# ATSAMG55J19 device description
Architecture: CORTEX-M4; Family: SAMG; Series: SAMG55
Registers are 32-bit, read-write, no defined reset value unless marked. A register's access mark holds for its fields unless they carry their own. Offsets are from the block's base; [hi:lo] are bit positions; {n}, {i} and the like mark numbered series.

## PMC — Power Management Controller
Instances: PMC 0x400E0400
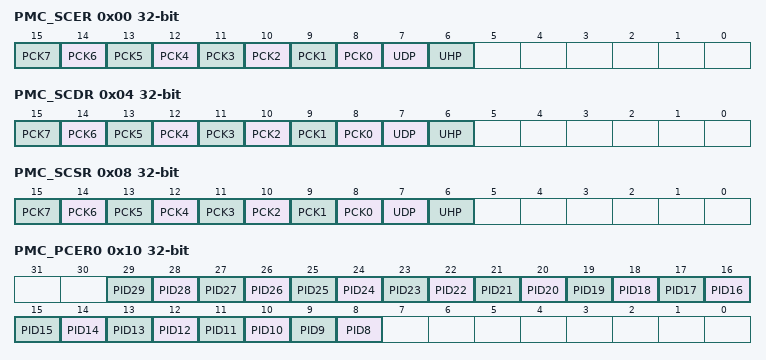
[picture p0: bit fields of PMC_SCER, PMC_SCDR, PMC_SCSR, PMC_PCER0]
0x00 PMC_SCER wo (atomic set of PMC_SCSR) — System Clock Enable Register
  [n+8] PCK{n} (n=0..7) — Programmable Clock {n} Output Enable
  [7] UDP — USB Device Port Clock Enable
  [6] UHP — USB Host Port Clock Enable
0x04 PMC_SCDR wo (atomic clear of PMC_SCSR) — System Clock Disable Register
  [n+8] PCK{n} (n=0..7) — Programmable Clock {n} Output Disable
  [7] UDP
  [6] UHP — USB Host Port Clock Disable
0x08 PMC_SCSR ro — System Clock Status Register
  [n+8] PCK{n} (n=0..7) — Programmable Clock {n} Output Status
  [7] UDP
  [6] UHP — USB Host Port Clock Status
0x10 PMC_PCER0 wo (atomic set of PMC_PCSR0) — Peripheral Clock Enable Register 0
  [n] PID{n} (n=8..29) — Peripheral Clock {n} Enable
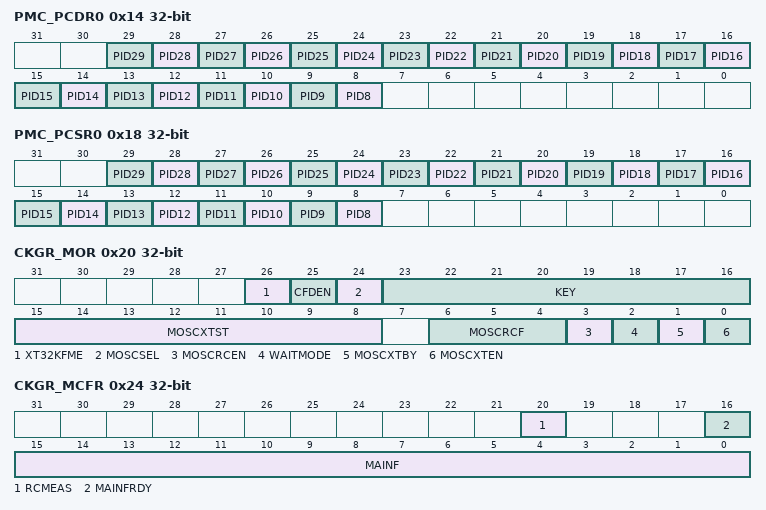
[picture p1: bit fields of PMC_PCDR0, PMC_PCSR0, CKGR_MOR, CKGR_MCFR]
0x14 PMC_PCDR0 wo (atomic clear of PMC_PCSR0) — Peripheral Clock Disable Register 0
  [n] PID{n} (n=8..29) — Peripheral Clock {n} Disable
0x18 PMC_PCSR0 ro — Peripheral Clock Status Register 0
  [n] PID{n} (n=8..29) — Peripheral Clock {n} Status
0x20 CKGR_MOR — Main Oscillator Register
  [26] XT32KFME — 32.768 kHz Crystal Oscillator Frequency Monitoring Enable
  [25] CFDEN — Clock Failure Detector Enable
  [24] MOSCSEL — Main Oscillator Selection
  [23:16] KEY — Write Access Password
    55=PASSWD (Writing any other value in this field aborts the write operation.Always reads as 0.)
  [15:8] MOSCXTST — Main Crystal Oscillator Start-up Time
  [6:4] MOSCRCF — Main On-Chip RC Oscillator Frequency Selection
    0=_8_MHz (The Fast RC Oscillator frequency is at 8 MHz (default)); 1=_16_MHz (The Fast RC Oscillator frequency is at 16 MHz); 2=_24_MHz (The Fast RC Oscillator frequency is at 24 MHz)
  [3] MOSCRCEN — Main On-Chip RC Oscillator Enable
  [2] WAITMODE — Wait Mode Command (Write-only)
  [1] MOSCXTBY — Main Crystal Oscillator Bypass
  [0] MOSCXTEN — Main Crystal Oscillator Enable
0x24 CKGR_MCFR — Main Clock Frequency Register
  [20] RCMEAS — RC Oscillator Frequency Measure (write-only)
  [16] MAINFRDY — Main Clock Frequency Measure Ready
  [15:0] MAINF — Main Clock Frequency
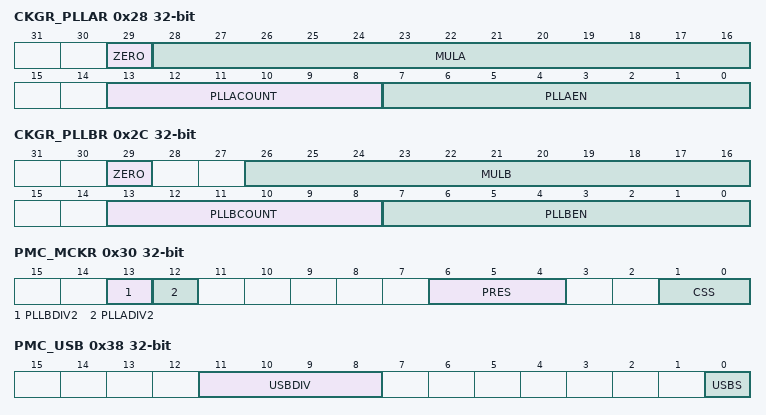
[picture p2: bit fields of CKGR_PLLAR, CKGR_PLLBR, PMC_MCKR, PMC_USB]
0x28 CKGR_PLLAR — PLLA Register
  [29] ZERO — Must Be Written to 0
  [28:16] MULA — PLLA Multiplier
  [13:8] PLLACOUNT — PLLA Counter
  [7:0] PLLAEN — PLLA Control
0x2C CKGR_PLLBR — PLLB Register
  [29] ZERO — Must Be Written to 0
  [26:16] MULB — PLLB Multiplier
  [13:8] PLLBCOUNT — PLLB Counter
  [7:0] PLLBEN — PLLB Control
0x30 PMC_MCKR — Master Clock Register
  [13] PLLBDIV2
  [12] PLLADIV2 — PLLA Divisor by 2
  [6:4] PRES — Processor Clock Prescaler
    0=CLK_1 (Selected clock); 1=CLK_2 (Selected clock divided by 2); 2=CLK_4 (Selected clock divided by 4); 3=CLK_8 (Selected clock divided by 8); 4=CLK_16 (Selected clock divided by 16); 5=CLK_32 (Selected clock divided by 32); 6=CLK_64 (Selected clock divided by 64); 7=CLK_3 (Selected clock divided by 3)
  [1:0] CSS — Master Clock Source Selection
    0=SLOW_CLK (Slow Clock is selected); 1=MAIN_CLK (Main Clock is selected); 2=PLLA_CLK (PLLA Clock is selected); 3=PLLB_CLK (PLLBClock is selected)
0x38 PMC_USB — USB Clock Register
  [11:8] USBDIV — Divider for USB Clock
  [0] USBS — USB Input Clock Selection
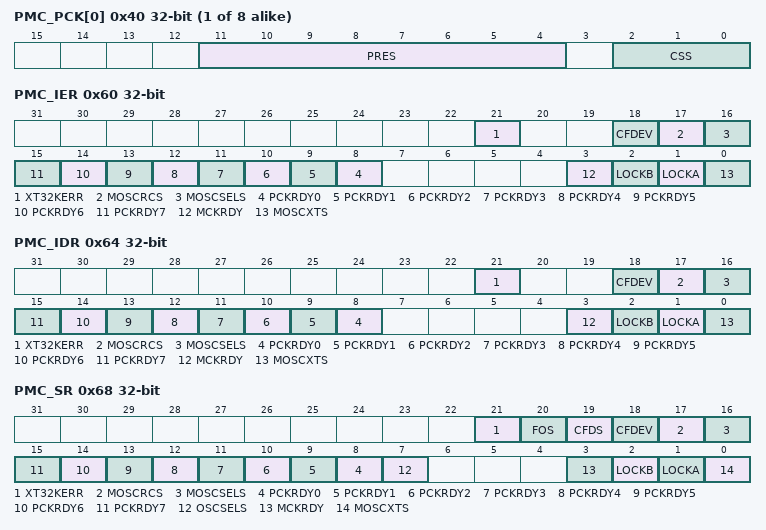
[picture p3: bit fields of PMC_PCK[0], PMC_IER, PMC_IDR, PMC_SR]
{0x40+4i} PMC_PCK[{i}] (i=0..7) — Programmable Clock 0 Register 0
  [11:4] PRES — Programmable Clock Prescaler
  [2:0] CSS — Master Clock Source Selection
    0=SLOW_CLK (Slow Clock is selected); 1=MAIN_CLK (Main Clock is selected); 2=PLLA_CLK (PLLA Clock is selected); 3=PLLB_CLK (PLLB Clock is selected); 4=MCK (Master Clock is selected)
0x60 PMC_IER wo (atomic set of PMC_IMR) — Interrupt Enable Register
  [21] XT32KERR — 32.768 kHz Crystal Oscillator Error Interrupt Enable
  [18] CFDEV — Clock Failure Detector Event Interrupt Enable
  [17] MOSCRCS — Main On-Chip RC Status Interrupt Enable
  [16] MOSCSELS — Main Oscillator Selection Status Interrupt Enable
  [n+8] PCKRDY{n} (n=0..7) — Programmable Clock Ready {n} Interrupt Enable
  [3] MCKRDY — Master Clock Ready Interrupt Enable
  [2] LOCKB — PLLB Lock Interrupt Enable
  [1] LOCKA — PLLA Lock Interrupt Enable
  [0] MOSCXTS — Main Crystal Oscillator Status Interrupt Enable
0x64 PMC_IDR wo (atomic clear of PMC_IMR) — Interrupt Disable Register
  [21] XT32KERR — 32.768 kHz Crystal Oscillator Error Interrupt Disable
  [18] CFDEV — Clock Failure Detector Event Interrupt Disable
  [17] MOSCRCS — Main On-Chip RC Status Interrupt Disable
  [16] MOSCSELS — Main Oscillator Selection Status Interrupt Disable
  [n+8] PCKRDY{n} (n=0..7) — Programmable Clock Ready {n} Interrupt Disable
  [3] MCKRDY — Master Clock Ready Interrupt Disable
  [2] LOCKB — PLLB Lock Interrupt Disable
  [1] LOCKA — PLLA Lock Interrupt Disable
  [0] MOSCXTS — Main Crystal Oscillator Status Interrupt Disable
0x68 PMC_SR ro — Status Register
  [21] XT32KERR — Slow Crystal Oscillator Error
  [20] FOS — Clock Failure Detector Fault Output Status
  [19] CFDS — Clock Failure Detector Status
  [18] CFDEV — Clock Failure Detector Event
  [17] MOSCRCS — Main On-Chip RC Oscillator Status
  [16] MOSCSELS — Main Oscillator Selection Status
  [n+8] PCKRDY{n} (n=0..7) — Programmable Clock Ready Status
  [7] OSCSELS — Slow Clock Oscillator Selection
  [3] MCKRDY — Master Clock Status
  [2] LOCKB — PLLB Lock Status
  [1] LOCKA — PLLA Lock Status
  [0] MOSCXTS — Main Crystal Oscillator Status
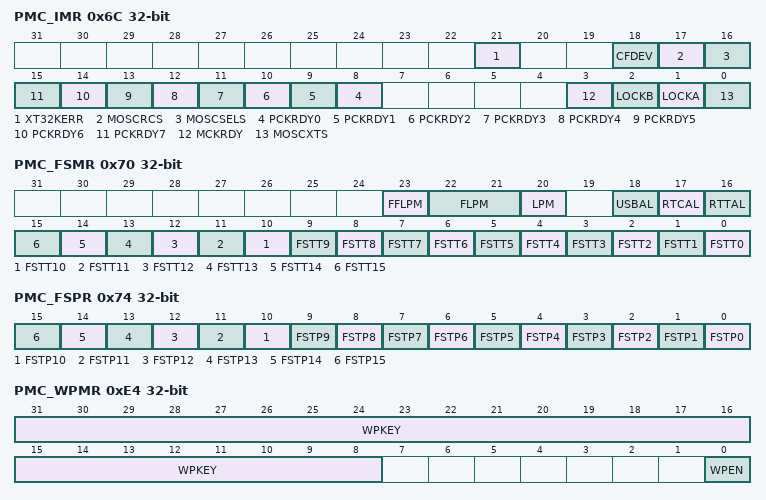
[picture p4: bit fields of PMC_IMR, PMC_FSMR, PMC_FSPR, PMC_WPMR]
0x6C PMC_IMR ro (atomic read) — Interrupt Mask Register
  [21] XT32KERR — 32.768 kHz Crystal Oscillator Error Interrupt Mask
  [18] CFDEV — Clock Failure Detector Event Interrupt Mask
  [17] MOSCRCS — Main On-Chip RC Status Interrupt Mask
  [16] MOSCSELS — Main Oscillator Selection Status Interrupt Mask
  [n+8] PCKRDY{n} (n=0..7) — Programmable Clock Ready {n} Interrupt Mask
  [3] MCKRDY — Master Clock Ready Interrupt Mask
  [2] LOCKB — PLLB Lock Interrupt Mask
  [1] LOCKA — PLLA Lock Interrupt Mask
  [0] MOSCXTS — Main Crystal Oscillator Status Interrupt Mask
0x70 PMC_FSMR — Fast Startup Mode Register
  [23] FFLPM — Force Flash Low-power Mode
  [22:21] FLPM — Flash Low-power Mode
    0=FLASH_STANDBY (Flash is in Standby Mode when system enters Wait Mode); 1=FLASH_DEEP_POWERDOWN (Flash is in Deep-power-down mode when system enters Wait Mode); 2=FLASH_IDLE (Idle mode)
  [20] LPM — Low-power Mode
  [18] USBAL — USB Alarm Enable
  [17] RTCAL — RTC Alarm Enable
  [16] RTTAL — RTT Alarm Enable
  [n] FSTT{n} (n=0..15) — Fast Startup Input Enable {n}
0x74 PMC_FSPR — Fast Startup Polarity Register
  [n] FSTP{n} (n=0..15) — Fast Startup Input Polarityx
0x78 PMC_FOCR wo — Fault Output Clear Register
  [0] FOCLR — Fault Output Clear
0xE4 PMC_WPMR — Write Protection Mode Register
  [31:8] WPKEY — Write Protection Key
    0x504D43=PASSWD (Writing any other value in this field aborts the write operation of the WPEN bit. Always reads as 0.)
  [0] WPEN — Write Protection Enable
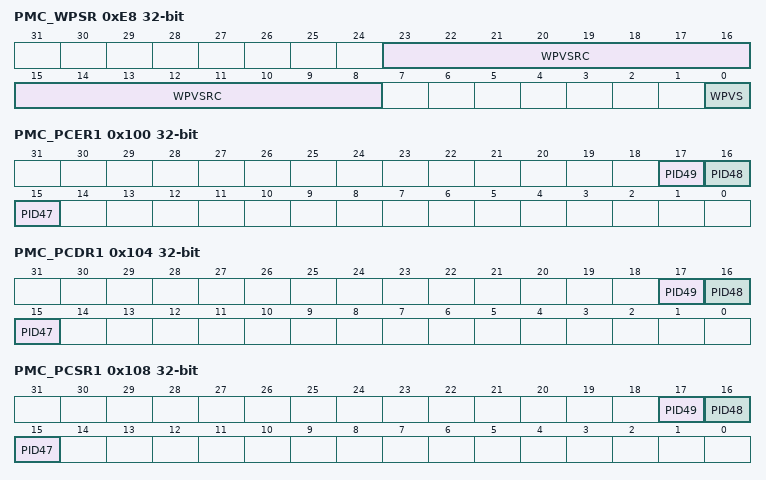
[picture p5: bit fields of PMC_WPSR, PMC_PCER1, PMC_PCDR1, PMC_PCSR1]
0xE8 PMC_WPSR ro — Write Protection Status Register
  [23:8] WPVSRC — Write Protection Violation Source
  [0] WPVS — Write Protection Violation Status
0x100 PMC_PCER1 wo (atomic set of PMC_PCSR1) — Peripheral Clock Enable Register 1
  [17] PID49 — Peripheral Clock 49 Enable
  [16] PID48 — Peripheral Clock 48 Enable
  [15] PID47 — Peripheral Clock 47 Enable
0x104 PMC_PCDR1 wo (atomic clear of PMC_PCSR1) — Peripheral Clock Disable Register 1
  [17] PID49 — Peripheral Clock 49 Disable
  [16] PID48 — Peripheral Clock 48 Disable
  [15] PID47 — Peripheral Clock 47 Disable
0x108 PMC_PCSR1 ro — Peripheral Clock Status Register 1
  [17] PID49 — Peripheral Clock 49 Status
  [16] PID48 — Peripheral Clock 48 Status
  [15] PID47 — Peripheral Clock 47 Status
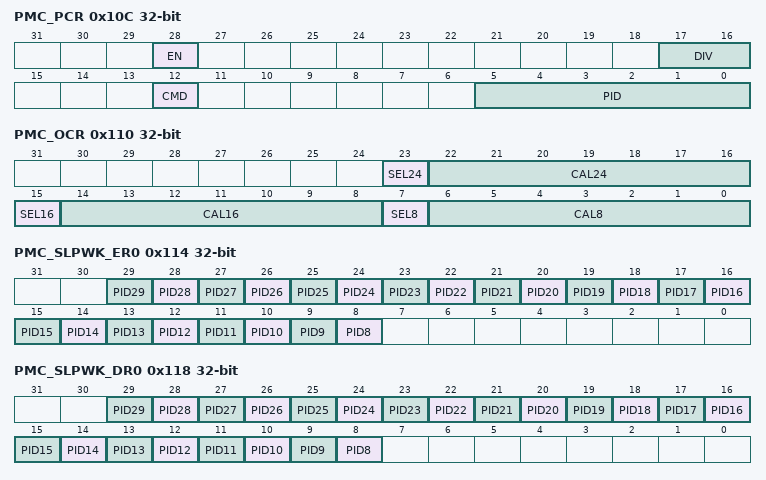
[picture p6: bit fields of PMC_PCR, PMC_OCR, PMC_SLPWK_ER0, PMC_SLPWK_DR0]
0x10C PMC_PCR — Peripheral Control Register
  [28] EN — Enable
  [17:16] DIV — Divisor Value
    0=PERIPH_DIV_MCK (Peripheral clock is MCK); 1=PERIPH_DIV2_MCK (Peripheral clock is MCK/2); 2=PERIPH_DIV4_MCK (Peripheral clock is MCK/4); 3=PERIPH_DIV8_MCK (Peripheral clock is MCK/8)
  [12] CMD — Command
  [5:0] PID — Peripheral ID
0x110 PMC_OCR — Oscillator Calibration Register
  [23] SEL24 — Selection of RC Oscillator Calibration bits for 24 MHz
  [22:16] CAL24 — RC Oscillator Calibration bits for 24 MHz
  [15] SEL16 — Selection of RC Oscillator Calibration bits for 16 MHz
  [14:8] CAL16 — RC Oscillator Calibration bits for 16 MHz
  [7] SEL8 — Selection of RC Oscillator Calibration bits for 8 MHz
  [6:0] CAL8 — RC Oscillator Calibration bits for 8 MHz
0x114 PMC_SLPWK_ER0 wo (atomic set of PMC_SLPWK_SR0) — SleepWalking Enable Register 0
  [n] PID{n} (n=8..29) — Peripheral {n} SleepWalking Enable
0x118 PMC_SLPWK_DR0 wo (atomic clear of PMC_SLPWK_SR0) — SleepWalking Disable Register 0
  [n] PID{n} (n=8..29) — Peripheral {n} SleepWalking Disable
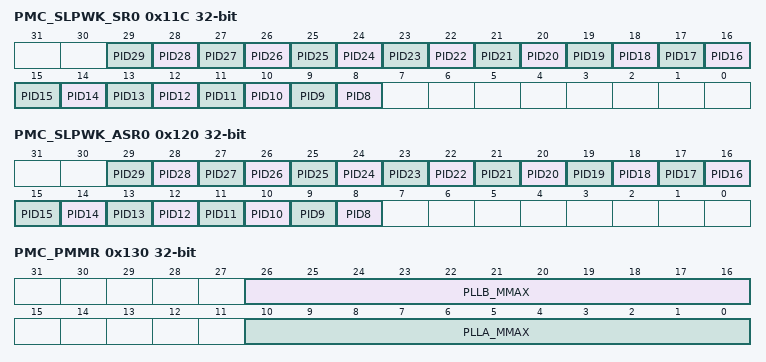
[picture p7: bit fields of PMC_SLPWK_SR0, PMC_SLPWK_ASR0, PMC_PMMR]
0x11C PMC_SLPWK_SR0 ro — SleepWalking Status Register 0
  [n] PID{n} (n=8..29) — Peripheral {n} SleepWalking Status
0x120 PMC_SLPWK_ASR0 ro — SleepWalking Activity Status Register 0
  [n] PID{n} (n=8..29) — Peripheral {n} Activity Status
0x130 PMC_PMMR — PLL Maximum Multiplier Value Register
  [26:16] PLLB_MMAX — PLLB Maximum Allowed Multiplier Value
  [10:0] PLLA_MMAX — PLLA Maximum Allowed Multiplier Value
